# RN831X_RN861X_MCU register map
File version: v0.0.1
CPU: RN831X_RN861X_MCU r1p0, little endian, MPU, no FPU
Registers are 32-bit, read-write, reset 0x0 unless marked. A register's access mark holds for its fields unless they carry their own. Offsets are from the block's base; [hi:lo] are bit positions.

## MAILBOX_CORE0 — MAILBOX Module core0
Base 0x3000C000
Same registers: MAILBOX_CORE1 0xB000C000
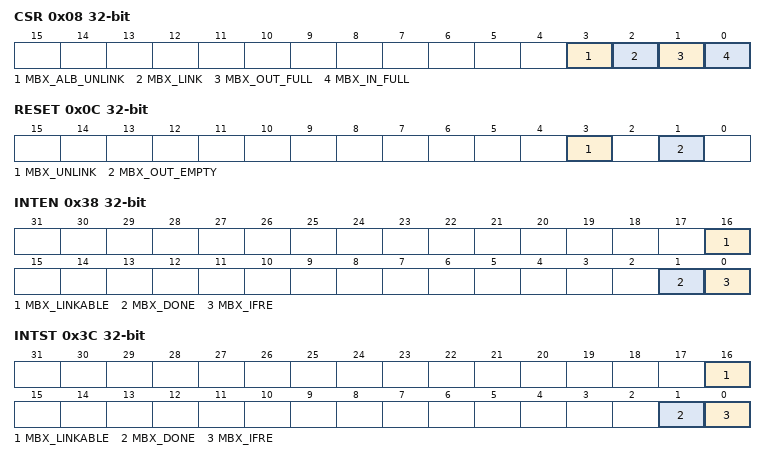
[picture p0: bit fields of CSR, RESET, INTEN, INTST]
0x08 CSR — Control/Status Register
  [3] MBX_ALB_UNLINK — Write 1 to disconnect from mailbox and clear CSR.MBX_LINK bit (only core1 can access).
  [2] MBX_LINK — Write 1 to connect mailbox channel. If successful, this bit sets automatically to 1 (only core1 can access).
  [1] MBX_OUT_FULL — Output mailbox status bit.For CORE0: Write 1 to indicate output mailbox full, sets INTST.MBX_DONE. For CORE1: Write 1 to clear output mailbox status.
  [0] MBX_IN_FULL — Input mailbox status bit. For CORE0: Write 1 to clear input mailbox status. For CORE1: Write 1 to indicate input mailbox full, set INTST.MBX_IFRE
0x0C RESET — Reset Register (only core0 can access)
  [3] MBX_UNLINK — CORE0 writes 1 to this bit to clear CSR.MBX_LINKED bit and disconnect CORE1 from mailbox.
  [1] MBX_OUT_EMPTY — CORE0 writes 1 to this bit to clear CSR.MBX_OUT_FULL.
0x10 LINKID access not given — Connection Host ID Register
  [0] ID — Read back the host ID number that has connected to the input mailbox
0x18 LOCKOUT access not given
  [0] MBX — Mailbox lock status, accessible only by CORE1
0x38 INTEN — CORE0/CORE1 Interrupt Enable Register
  [16] MBX_LINKABLE — CORE1 mailbox connectable interrupt enable.
  [1] MBX_DONE — CORE0(CORE1) output mailbox empty(full) interrupt enable.
  [0] MBX_IFRE — CORE0(CORE1) input mailbox full(empty) interrupt enable.
0x3C INTST — CORE0/CORE1 Interrupt Status Register
  [16] MBX_LINKABLE — CORE1 mailbox connectable interrupt flag
  [1] MBX_DONE — Output mailbox interrupt flag
  [0] MBX_IFRE — Input mailbox interrupt flag.
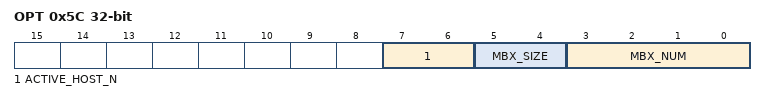
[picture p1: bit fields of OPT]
0x5C OPT ro — Internal Configuration Status Register
  [7:6] ACTIVE_HOST_N — Indicates number of cores that can connect to mailbox. Current system only has CORE1
  [5:4] MBX_SIZE — Hardware-specified actual implementation size of each input/output mailbox
    0=128BYTE (128Bytes); 1=256BYTE (256Bytes (default)); 2=512BYTE (512Bytes); 3=1024BYTE (1024Bytes)
  [3:0] MBX_NUM — Indicates number of existing input/output mailbox pairs, Current system only has 1 mailbox pair, hardware fixed to 1
0x60 FROZE access not given — Freeze Host Access Configuration Register (only core0 can access)
  [31:0] FROZE — CORE0 writes 1 to lock the core number that can access MAILBOX registers
0x64 ID_VAL access not given — Accessible Host ID Register (only core0 can access)
  [0] ID_VAL — Written by CORE0 with the core host_id number that can access MAILBOX registers (CORE1 core host_id is 0)
0xE4 ID_MASK access not given — Accessible Host ID Mask Register (only core0 can access)
  [0] MASK — Written by CORE0 with the core host_id mask that can access MAILBOX registers
0x300 MBX_KEY0 access not given — CORE0 Password Register (only core0 can access)
  [31:0] MBX_KEY0 — CORE0 writes password register, password is 0xA538E827
0x304 MBX_KEY1 access not given — CORE1 Password Register (only core1 can access)
  [31:0] MBX_KEY1 — CORE1 writes password register, password is 0xA538EC63
0x2000 MESSAGE access not given — Mailbox Message Register. 256 Bytes SRAM.
  [31:0] MSG — 256 Bytes Mailbox Message SRAM

## SIMPTC0_0_CORE0 — simple time counter
Base 0x200A4000
Same registers: SIMPTC0_1_CORE0 0x200A4010, SIMPTC0_2_CORE0 0x200A4020, SIMPTC0_3_CORE0 0x200A4030, SIMPTC1_0_CORE0 0x200A8000, SIMPTC1_1_CORE0 0x200A8010, SIMPTC1_2_CORE0 0x200A8020, SIMPTC1_3_CORE0 0x200A8030, SIMPTC2_0_CORE0 0x200AC000, SIMPTC2_1_CORE0 0x200AC010, SIMPTC2_2_CORE0 0x200AC020, SIMPTC2_3_CORE0 0x200AC030, SIMPTC3_0_CORE0 0x200B0000, SIMPTC3_1_CORE0 0x200B0010, SIMPTC3_2_CORE0 0x200B0020, SIMPTC3_3_CORE0 0x200B0030, SIMPTC0_0_CORE1 0xA00A4000, SIMPTC0_1_CORE1 0xA00A4010, SIMPTC0_2_CORE1 0xA00A4020, SIMPTC0_3_CORE1 0xA00A4030, SIMPTC1_0_CORE1 0xA00A8000, SIMPTC1_1_CORE1 0xA00A8010, SIMPTC1_2_CORE1 0xA00A8020, SIMPTC1_3_CORE1 0xA00A8030, SIMPTC2_0_CORE1 0xA00AC000, SIMPTC2_1_CORE1 0xA00AC010, SIMPTC2_2_CORE1 0xA00AC020, SIMPTC2_3_CORE1 0xA00AC030, SIMPTC3_0_CORE1 0xA00B0000, SIMPTC3_1_CORE1 0xA00B0010, SIMPTC3_2_CORE1 0xA00B0020, SIMPTC3_3_CORE1 0xA00B0030
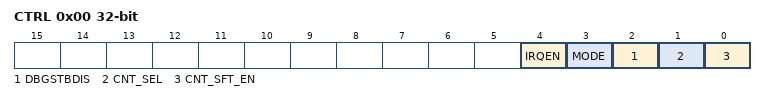
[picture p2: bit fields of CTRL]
0x00 CTRL access not given — SIMPTC control register
  [4] IRQEN — SIMP_TCx_x interrupt enable bit
  [3] MODE — SIMP_TCx_x count mode selection bit
    0=SINGLE (SIMP_TCx_x select as Single Count); 1=CONTINUE (SIMP_TCx_x select as Continuous Count)
  [2] DBGSTBDIS — SIMP_TCx_x debug standby disable bit
    0=PAUSE (halt counting when SoC halted by debugger); 1=COUNTINUE (keep counting when SoC halted by debugger)
  [1] CNT_SEL — SIMP_TCx_x counter enable source select
    0=SFT (enable counter source select as soft config); 1=AOS (enable counter source select as AOS)
  [0] CNT_SFT_EN — SIMP_TCx_x counter soft enable bit
    0=EN (enable); 1=DIS (disable)
0x04 DN access not given — SIMPTC target counter register
  [31:0] DN — SIMPTC target counting value setting bits
0x08 VAL access not given — SIMPTC counter register bits
  [31:0] VAL — SIMPTC current count register bits
0x0C IF access not given — SIMPTC interrupt flag bits
  [0] OV — SIMPTC counter overflow interrrupt flag

## TIMER — Timer Unit
Base 0xE0030000
0x00 MTIME_LO access not given — Reflect the lower 32-bit value of mtime.
0x04 MTIME_HI access not given — Reflect the upper 32-bit value of mtime.
0x08 MTIMECMP_LO access not given — Set the lower 32-bit value of mtimecmp.
0x0C MTIMECMP_HI access not given — Set the upper 32-bit value of mtimecmp.
0xFEC MTIME_SRW_CTRL access not given — Control S-mode can access this timer or not.
  [0] MTIME_SRW_CTRL
0xFF0 MSFTRST access not given — Generate soft-reset request.
  [31] MSFTRST
0xFF4 SSIP access not given — Generate the Software Interrupt in S-mode.
  [2:0] SSIP
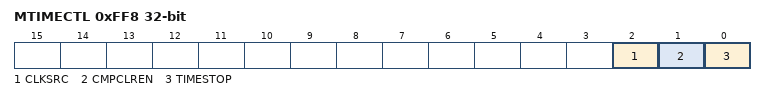
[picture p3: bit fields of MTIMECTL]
0xFF8 MTIMECTL — Control some features of the time counter.
  [2] CLKSRC — Select the source of increment frequency.
  [1] CMPCLREN — Control the timer count to clear-to-zero or not.
  [0] TIMESTOP — Control the timer count or pause.
0xFFC MSIP access not given — Generate the Software Interrupt.
  [0] MSIP

## WDT_CORE0 — WDT Module core0
Base 0x20100000
Same registers: WDT_CORE1 0xA0100000
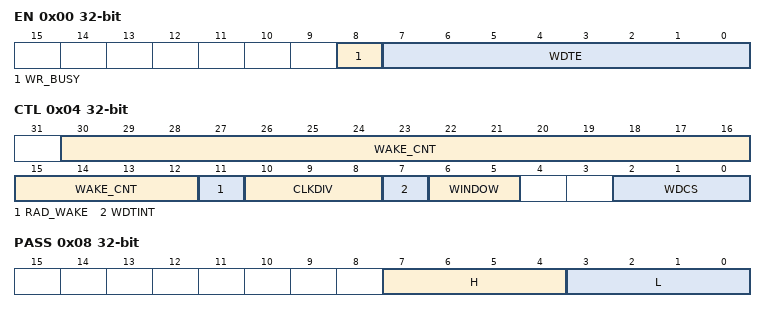
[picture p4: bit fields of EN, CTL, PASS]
0x00 EN access per field — Watchdog enable register
  [8] WR_BUSY rw — Write busy state of WDT
  [7:0] WDTE ro — Reload bits of WDT
0x04 CTL — Watchdog control register
  [30:12] WAKE_CNT — Random wake counting bis
  [11] RAD_WAKE — Enable bit of random wake
  [10:8] CLKDIV — Clock division of WDT
    0=DIV0 (Clock no divider); 1=DIV2 (Clock divider by 2); 2=DIV4 (Clock divider by 4); 3=DIV8 (Clock divider by 8); 4=DIV16 (Clock divider by 16); 5=DIV32 (Clock divider by 32); 6=DIV64 (Clock divider by 64); 7=DIV128 (Clock divider by 128)
  [7] WDTINT — Early wake interrup of WDT
  [6:5] WINDOW — Valid reload window
    0=ONEQUARTER (One quarter of overflow time); 1=HALF (Half of overflow time); 2=THREEQUARTERS (Three quarters of overflow time); 3=FULL (Full of overflow time)
  [2:0] WDCS — Overflow time configuration
    0=Overflow time 15.625ms; 1=Overflow time 31.25ms; 2=Overflow time 125ms; 3=Overflow time 500ms; 4=Overflow time 1s; 5=Overflow time 2s; 6=Overflow time 4s; 7=Overflow time 8s
0x08 PASS — Password register
  [7:4] H — Password high bits
  [3:0] L — Password low bits
0x14 HALT access not given reset 0x5A5A5A7E — Control whether to stop counting when the CPU is in halt state
0x18 STBY access not given reset 0x5A5A5A38 — Control whether to stop counting when the CPU is in sleep state
0x1C STOP access not given reset 0x55AAAA55 — Control whether to stop counting when the CPU is in stop state
0x20 CNT access not given — Counting of WDT
  [18:0] CNT — Counting bits of WDT
